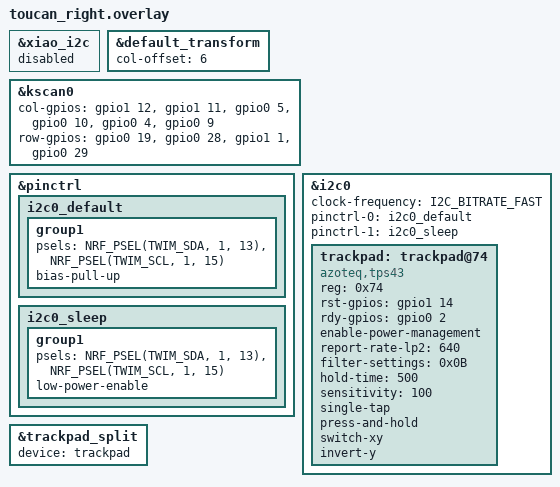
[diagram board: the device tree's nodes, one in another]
#include "toucan.dtsi"
#include <input/processors.dtsi>
#include <dt-bindings/zmk/input_transform.h>

&xiao_i2c {
    status = "disabled";
};

&default_transform {
    col-offset = <6>;
};

&kscan0 {
    col-gpios
    = <&gpio1 12 GPIO_ACTIVE_HIGH>
    , <&gpio1 11 GPIO_ACTIVE_HIGH>
    , <&gpio0 5 GPIO_ACTIVE_HIGH>
    , <&gpio0 10 GPIO_ACTIVE_HIGH>
    , <&gpio0 4 GPIO_ACTIVE_HIGH>
    , <&gpio0 9 GPIO_ACTIVE_HIGH>
    ;

    row-gpios
    = <&gpio0 19 (GPIO_ACTIVE_HIGH | GPIO_PULL_DOWN)>
    , <&gpio0 28 (GPIO_ACTIVE_HIGH | GPIO_PULL_DOWN)>
    , <&gpio1 1 (GPIO_ACTIVE_HIGH | GPIO_PULL_DOWN)>
    , <&gpio0 29 (GPIO_ACTIVE_HIGH | GPIO_PULL_DOWN)>
    ;
};

&pinctrl {
    i2c0_default: i2c0_default {
        group1 {
            psels = <NRF_PSEL(TWIM_SDA, 1, 13)>,
                    <NRF_PSEL(TWIM_SCL, 1, 15)>;
            bias-pull-up;
        };
    };

    i2c0_sleep: i2c0_sleep {
        group1 {
            psels = <NRF_PSEL(TWIM_SDA, 1, 13)>,
                    <NRF_PSEL(TWIM_SCL, 1, 15)>;
            low-power-enable;
        };
    };
};

&i2c0 {
   status = "okay";
   clock-frequency = <I2C_BITRATE_FAST>;
   pinctrl-0 = <&i2c0_default>;
   pinctrl-1 = <&i2c0_sleep>;
   pinctrl-names = "default", "sleep";

   trackpad: trackpad@74 {
        compatible = "azoteq,tps43";
        reg = <0x74>;
        status = "okay";

        rst-gpios = <&gpio1 14 GPIO_ACTIVE_HIGH>;
        rdy-gpios = <&gpio0 2 GPIO_ACTIVE_HIGH>;

        enable-power-management;
        report-rate-lp2 = <640>; // 640ms LP2 report rate: 55uA vs 174uA at the default 160ms
        filter-settings = <0x0B>;
        hold-time = <500>;
        sensitivity = <100>;

        single-tap;
        press-and-hold;

        // Raw axes come in swapped/rotated relative to the case: left was
        // tracking as up, up was tracking as right. switch-xy realigns the
        // axes; invert-y corrects the resulting up/down direction.
        switch-xy;
        invert-y;
        // If left/right end up reversed instead after this, swap invert-y
        // for invert-x.
    };
};

&trackpad_split {
    device = <&trackpad>;

    // Optional
    // input-processors = <&zip_xy_transform (INPUT_TRANSFORM_XY_SWAP | INPUT_TRANSFORM_X_INVERT | INPUT_TRANSFORM_Y_INVERT)>;
};
